# SN32F770 register map
Vendor: SONiX Technology Co., Ltd.; Series: SN32F770; File version: 1.4
CPU: CM0 r0p0, little endian, no MPU, no FPU, 2 interrupt priority bits
Registers are 32-bit, read-write, reset 0x0 unless marked. A register's access mark holds for its fields unless they carry their own. Offsets are from the block's base; [hi:lo] are bit positions; {n}, {i} and the like mark numbered series.

## SN_SYS1 — System Control Registers
Base 0x4005E000
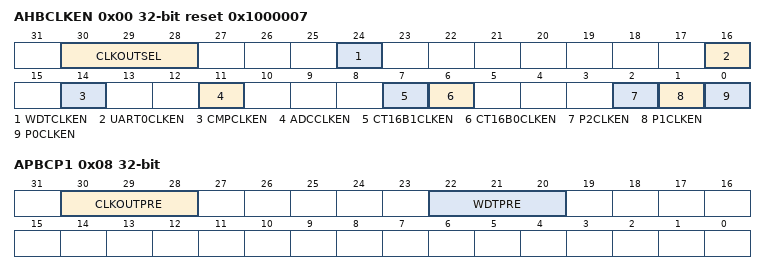
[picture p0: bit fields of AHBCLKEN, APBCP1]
0x00 AHBCLKEN reset 0x1000007 — Offset:0x00 AHB Clock Enable Register
  [30:28] CLKOUTSEL — Clock output source selection
    0=000b (Disable); 1=001b (ILRC); 4=100b (HCLK); 5=101b (IHRC)
  [24] WDTCLKEN — Enable AHB clock for WDT
    0=Disable; 1=Enable
  [16] UART0CLKEN — Enable AHB clock for UART0
    0=Disable; 1=Enable
  [14] CMPCLKEN — Enable AHB clock for CMP
    0=Disable; 1=Enable
  [11] ADCCLKEN — Enable AHB clock for ADC
    0=Disable; 1=Enable
  [7] CT16B1CLKEN — Enable AHB clock for CT16B1
    0=Disable; 1=Enable
  [6] CT16B0CLKEN — Enable AHB clock for CT16B0
    0=Disable; 1=Enable
  [2] P2CLKEN — Enable AHB clock for P2
    0=Disable; 1=Enable
  [1] P1CLKEN — Enable AHB clock for P1
    0=Disable; 1=Enable
  [0] P0CLKEN — Enable AHB clock for P0
    0=Disable; 1=Enable
0x04 APBCP0 — Offset:0x04 APB Clock Prescale Register 0
  [18:16] ADCPRE — ADC APB clock source prescaler
    0=000b (HCLK/1); 1=001b (HCLK/2); 2=010b (HCLK/4); 3=011b (HCLK/8); 4=100b (HCLK/16)
0x08 APBCP1 — Offset:0x08 APB Clock Prescale Register 1
  [30:28] CLKOUTPRE — CLKOUT APB clock source prescaler
    0=000b (FCLKOUT/1); 1=001b (FCLKOUT/2); 2=010b (FCLKOUT/4); 3=011b (FCLKOUT/8); 4=100b (FCLKOUT/16); 5=101b (FCLKOUT/32); 6=110b (FCLKOUT/64); 7=111b (FCLKOUT/128)
  [22:20] WDTPRE — WDT APB clock source prescaler
    0=000b (WDT_PCLK = WDT clock source / 1); 1=001b (WDT_PCLK = WDT clock source / 2); 2=010b (WDT_PCLK = WDT clock source / 4); 3=011b (WDT_PCLK = WDT clock source / 8); 4=100b (WDT_PCLK = WDT clock source / 16); 5=101b (WDT_PCLK = WDT clock source / 32)

## SN_PMU — Power Management Unit
Base 0x40032000
0x40 CTRL — Offset:0x40 PMU Control Register
  [2:0] MODE — Low Power mode selection
    0=Disable Low-power mode; 2=Deep-sleep mode (WFI instruction will make MCU enter Deep-sleep mode); 4=Sleep mode (WFI instruction will make MCU enter Sleep mode)

## SN_ADC — ADC
Base 0x40026000
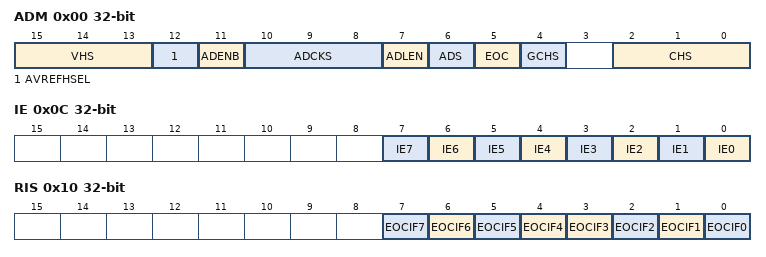
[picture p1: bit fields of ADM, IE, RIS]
0x00 ADM — Offset:0x00 ADC Management Register
  [15:13] VHS — Internal Ref. voltage source
    0=000b (Internal 2.0V as ADC internal reference high voltage); 1=001b (Internal 3.0V as ADC internal reference high voltage); 2=010b (Internal 4.5V as ADC internal reference high voltage); 4=100b (VDD as ADC internal reference high voltage, Internal 2.0V as AIN10); 5=101b (VDD as ADC internal reference high voltage, Internal 3.0V as AIN10); 6=110b (VDD as ADC internal reference high voltage, Internal 4.5V as AIN10); 7=111b (VDD as ADC internal reference high voltage)
  [12] AVREFHSEL — ADC high reference voltage source
    0=Interal Ref. Voltage (P2.0 acts as GPIO or AIN0 pin); 1=External reference voltage (P2.0 acts as AVREFH pin)
  [11] ADENB — ADC enable
    0=Disable ADC; 1=Enable ADC
  [10:8] ADCKS — ADC clock source divider
    0=000b (ADC_PCLK/1); 1=001b (ADC_PCLK/2); 2=010b (ADC_PCLK/4); 3=011b (ADC_PCLK/8); 5=101b (ADC_PCLK/16); 6=110b (ADC_PCLK/32)
  [7] ADLEN — ADC resolution
    0=8-bit ADB; 1=12-bit ADB
  [6] ADS — ADC start control
    0=Stop (ADC stopped); 1=Start ADC conversion
  [5] EOC — ADC status
    0=Busy (ADC processing); 1=End (End of conversion)
  [4] GCHS — ADC global channel enable
    0=Disable AIN channel; 1=Enable AIN channel
  [2:0] CHS — ADC input channel
    {v}=AIN{v} (v=0..4); 5=AIN5(Internal reference voltage 4.5V/3V/2V); 6=VDD; 7=VSS
0x04 ADB ro — Offset:0x04 ADC Data Register
  [11:0] ADB — ADB11~ADB4 bits for 8-bit ADC, ADB11~ADB0 bits for 12-bit ADC
0x0C IE (reset mask 0x3F) — Offset:0x0C ADC Interrupt Enable Register
  [n] IE{n} (n=0..7) — AIN{n} interrupt enable
    0=Disable AIN{n} interrupt; 1=Enable (ADC interrupt is triggered when AIN{n} completes ADC conversion)
0x10 RIS (reset mask 0x3F) — Offset:0x10 ADC Raw Interrupt Status Register
  [n] EOCIF{n} (n=4..7) — AIN{n} interrupt flag
    0=No interrupt on AIN{n}; 1=Met interrupt requirements (AIN{n} completes ADC conversion)
  [3] EOCIF3 — AIN0 interrupt flag
    0=No interrupt on AIN3; 1=Met interrupt requirements (AIN3 completes ADC conversion)
  [2] EOCIF2 — AIN2 interrupt flag
    0=No interrupt on AIN2; 1=Met interrupt requirements (AIN2 completes ADC conversion)
  [1] EOCIF1 — AIN1 interrupt flag
    0=No interrupt on AIN1; 1=Met interrupt requirements (AIN1 completes ADC conversion)
  [0] EOCIF0 — AIN0 interrupt flag
    0=No interrupt on AIN0; 1=Met interrupt requirements (AIN0 completes ADC conversion)
